# USB3_PHY_TX register map
Vendor: Texas Instruments
Peripheral module from a debugger description file (folder am571x).
Registers are 32-bit, read-write, reset 0x0 unless marked. A register's access mark holds for its fields unless they carry their own. Offsets are as the file gives them; lines under a group give offsets from that group; [hi:lo] are bit positions; {n}, {i} and the like mark numbered series; 'fields as' and 'values as' point back to an identical list; <NAME> marks a mode.

## USB3_PHY_TX
0x0C USB3PHYTX_FUNC_CONFIG_REG access per field — Functional Configuration registers
  [31] MEM_INVPAIR rw — Invert polarity of TXP/TXN
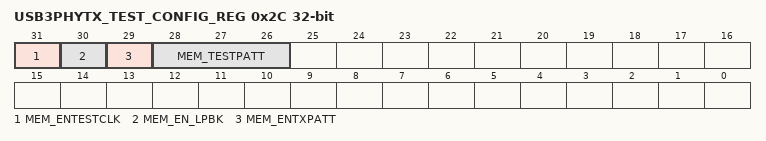
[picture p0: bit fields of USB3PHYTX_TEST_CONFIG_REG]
0x2C USB3PHYTX_TEST_CONFIG_REG — Test related configuration registers
  [31] MEM_ENTESTCLK — 0: USB Mode (uses PLL_CLK input clock)
  [30] MEM_EN_LPBK — Loopback enable for test
  [29] MEM_ENTXPATT — Enable Test pattern to input of the serializer instead of TD
  [28:26] MEM_TESTPATT — Select the LFSR mode to generate the required pattern 000: 31-bit LFSR mode 011: 23-bit LFSR mode 010: 7-bit LFSR mode 001: generate 1010 pattern 100: Fixed 31-bit value from PATTGEN_PRELOAD_VAL
0x30 USB3PHYTX_PATTGEN_PRELOAD — Pattern generator (31 bit) LFSR Seed or preload value
  [31:1] MEM_PATTGEN_PRELOAD_VAL — Preload value to the LFSR pattern generator
